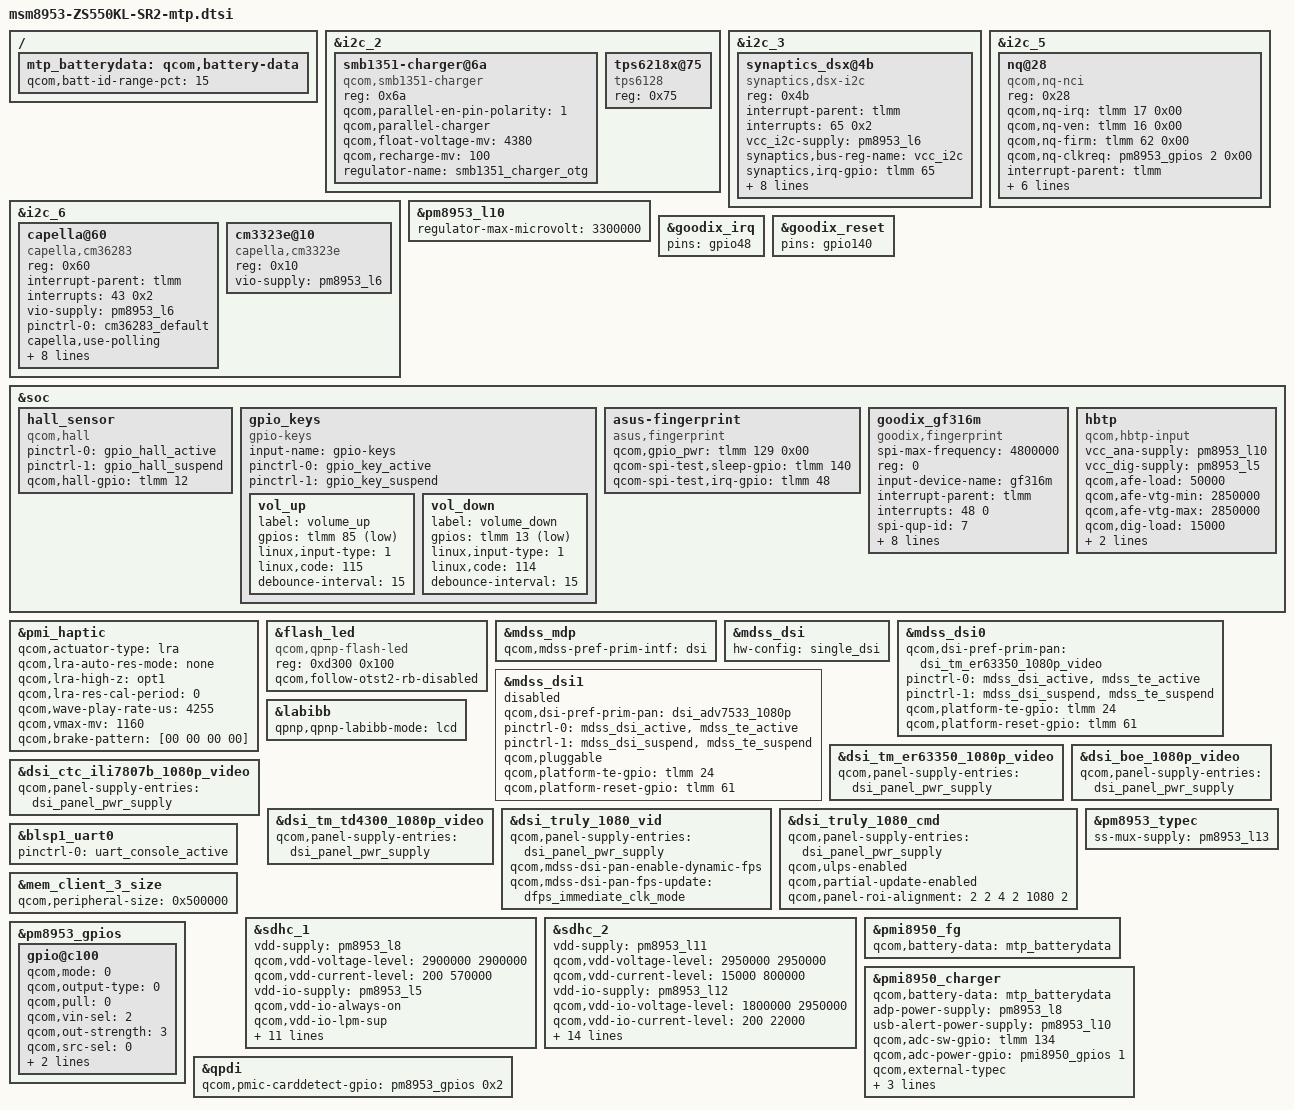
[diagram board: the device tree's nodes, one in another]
/*
 * Copyright (c) 2015-2016, The Linux Foundation. All rights reserved.
 *
 * This program is free software; you can redistribute it and/or modify
 * it under the terms of the GNU General Public License version 2 and
 * only version 2 as published by the Free Software Foundation.
 *
 * This program is distributed in the hope that it will be useful,
 * but WITHOUT ANY WARRANTY; without even the implied warranty of
 * MERCHANTABILITY or FITNESS FOR A PARTICULAR PURPOSE.  See the
 * GNU General Public License for more details.
 */

#include "msm8953-ZS550KL-SR2-pinctrl.dtsi"
#include "msm8953-ZS550KL-audio-mtp.dtsi"
#include "msm8953-ZS550KL-camera-sensor-mtp.dtsi"

&i2c_2 {
	/* Parallel-charger configuration */
	smb1351-charger@6a {
		compatible = "qcom,smb1351-charger";
		reg = <0x6a>;
		qcom,parallel-en-pin-polarity = <1>;
		qcom,parallel-charger;
		qcom,float-voltage-mv = <4380>;
		qcom,recharge-mv = <100>;
		regulator-name = "smb1351_charger_otg";
	};
	tps6218x@75{	
		compatible = "tps6128";
		reg = <0x75>;
		};
};

&i2c_3 { /* BLSP1 QUP3 */

	synaptics_dsx@4b {
		compatible = "synaptics,dsx-i2c";
		reg = <0x4b>;
		interrupt-parent = <&tlmm>;
		interrupts = <65 0x2>;
		//vdd_ana-supply = <&pm8941_l18>;
		vcc_i2c-supply = <&pm8953_l6>;
		//synaptics,pwr-reg-name = "vdd_ana";
		synaptics,bus-reg-name = "vcc_i2c";
		synaptics,irq-gpio = <&tlmm 65 0x00>;
		synaptics,irq-on-state = <0>;
		synaptics,irq-flags = <0x2008>; /* IRQF_ONESHOT | IRQF_TRIGGER_LOW */
		synaptics,power-delay-ms = <200>;
		synaptics,reset-delay-ms = <200>;
		synaptics,reset-on-state = <0>;
		synaptics,reset-active-ms = <20>;
		synaptics,ub-i2c-addr = <0x2c>;
		/* uncomment and update line below as appropriate if there are 0D buttons */
		synaptics,cap-button-codes = <158 102 139>;
		/* uncomment and update lines below as appropriate if there are virtual buttons */
		/* synaptics,vir-button-codes = <102 100 900 100 60 158 300 900 100 60>; */
		/* synaptics,max-y-for-2d = <800>; */
	};
};

&i2c_5 { /* BLSP2 QUP1 (NFC) */

	nq@28 {
		compatible = "qcom,nq-nci";
		reg = <0x28>;
		qcom,nq-irq = <&tlmm 17 0x00>;
		qcom,nq-ven = <&tlmm 16 0x00>;
		qcom,nq-firm = <&tlmm 62 0x00>;
		qcom,nq-clkreq = <&pm8953_gpios 2 0x00>;
		interrupt-parent = <&tlmm>;
		qcom,clk-src = "BBCLK2";
		interrupts = <17 0>;
		interrupt-names = "nfc_irq";
		pinctrl-names = "nfc_active", "nfc_suspend";
		pinctrl-0 = <&nfc_int_active &nfc_disable_active>;
		pinctrl-1 = <&nfc_int_suspend &nfc_disable_suspend>;
		clocks = <&clock_gcc clk_bb_clk2_pin>;
		clock-names = "ref_clk";
	};

};

&i2c_6 { /* BLSP2 QUP2 */
/*
	ap3045@1c{ 
		compatible = "di,ap3045";
		reg = <0x1c>;
		interrupt-parent = <&tlmm>;
		interrupts = <43 0>;
		vdd-supply = <&pm8953_l10>;
		//vcc_i2c-supply = <&pm8950_l6>;
		pinctrl-names = "default";
		pinctrl-0 = <&ap3045_default>;
		ap,use-polling;
		ap,interrupt-gpio = <&tlmm 43 0>;
		intel,ps-low-thres = < 70 >;
		intel,ps-hight-thres = < 80 >;
		intel,als-time = <0x10>;		
		intel,als-persis-time = <0x0f>;
		intel,int-ctrl = <0xA8>;
		intel,ps-gain = < 0x40 >; 
		intel,ps-led-control = <0x20>;
		intel,ps-time = <0x01>;  
		intel,als-gain = < 0x06 >;
		pm,class-name = "ap3045_class";
		pm,user-name = "ext_proximity_sensor";
		pm,state-D0 = "enable";
		pm,state-D3 = "disable";
		
	};
*/
	capella@60 {
		compatible = "capella,cm36283";
		reg = <0x60>;
		interrupt-parent = <&tlmm>;
		interrupts = <43 0x2>;
		//vdd-supply = <&pm8953_l10>;
		vio-supply = <&pm8953_l6>;
		pinctrl-names = "default";
		pinctrl-0 = <&cm36283_default>;
		capella,use-polling;
		capella,interrupt-gpio = <&tlmm 43 0x2>;
		capella,levels = <0x0A 0xA0 0xE1 0x140 0x280 0x500 0xA28 0x16A8 0x1F40 0x2800>;
		capella,ps_close_thd_set = <0x200>;
		capella,ps_away_thd_set = <0x100>;
		capella,ls_cmd = <0x04>; /* ALS_IT=80ms, INT_PERS=2*/
		capella,ps_conf1_val = <0x0006>;
		capella,ps_conf3_val = <0x3010>;
		};

	cm3323e@10{
		compatible = "capella,cm3323e";
		reg = <0x10>;
		//vdd-supply = <&pm8953_l10>;
		vio-supply = <&pm8953_l6>;
	};
};

&pm8953_l10 {
	regulator-max-microvolt = <3300000>;
};

&goodix_irq {
	pins = "gpio48";
};

&goodix_reset {
	pins = "gpio140";
};

&soc {
	hall_sensor {
		compatible = "qcom,hall";
		pinctrl-names = "hall_gpio_high","hall_gpio_low";
		pinctrl-0 = <&gpio_hall_active>;
		pinctrl-1 = <&gpio_hall_suspend>;
		qcom,hall-gpio = <&tlmm 12 0x0>;
	};

	gpio_keys {
		compatible = "gpio-keys";
		input-name = "gpio-keys";
		pinctrl-names = "tlmm_gpio_key_active","tlmm_gpio_key_suspend";
		pinctrl-0 = <&gpio_key_active>;
		pinctrl-1 = <&gpio_key_suspend>;

/* <ASUS_Lotta_Lu-2016/02/29> Note this beacuse because the gpio 87 is not for camera_focus ++++
		camera_focus {
			label = "camera_focus";
			gpios = <&tlmm 87 0x1>;
			linux,input-type = <1>;
			linux,code = <0x210>;
			debounce-interval = <15>;
		};
*/
/* <ASUS_Hank2_Liu-2016/08/02> Note this beacuse the gpio 86 is not for camera_snapshot ++++
		camera_snapshot {
			label = "camera_snapshot";
			gpios = <&tlmm 86 0x1>;
			linux,input-type = <1>;
			linux,code = <0x2fe>;
			debounce-interval = <15>;
		};
 <ASUS_Hank2_Liu-2016/08/02> Note this beacuse the gpio 86 is not for camera_snapshot ---- */
		vol_up {
			label = "volume_up";
			gpios = <&tlmm 85 0x1>;
			linux,input-type = <1>;
			linux,code = <115>;
			debounce-interval = <15>;
		};
//<ASUS_Hank2_Liu_20160217 Porting Volume Down Key> ++++++
		vol_down {
			label = "volume_down";
			gpios = <&tlmm 13 0x1>;
			linux,input-type = <1>;
			linux,code = <114>;
			debounce-interval = <15>;
		};
//<ASUS_Hank2_Liu_20160217 Porting Volume Down Key> ------
	};

	asus-fingerprint {
		compatible = "asus,fingerprint";
		//vcc-supply = <&pm8953_l6>;
		qcom,gpio_pwr = <&tlmm 129 0x00>;
		qcom-spi-test,sleep-gpio = <&tlmm 140 0x0>;
		qcom-spi-test,irq-gpio = <&tlmm 48 0x2008>;
	};

	goodix_gf316m {
		compatible = "goodix,fingerprint";
		spi-max-frequency = <4800000>;
		reg = <0>;
		input-device-name = "gf316m";
		interrupt-parent = <&tlmm>;
		interrupts = <48 0>;
		spi-qup-id = <7>;
		
		vcc_spi-supply  = <&pm8953_l6>;
		vdd_ana-supply  = <&pm8953_l6>;

		goodix,gpio_pwr = <&tlmm 129 0x00>;

		goodix,gpio_reset = <&tlmm 140 0x00>;
		goodix,gpio_irq = <&tlmm 48 0x00>;

		pinctrl-names = "goodix_irq_active";
		pinctrl-0 = <&goodix_irq_active>;

		clock-names = "iface_clk", "core_clk";
		clocks = <&clock_gcc clk_gcc_blsp2_ahb_clk>,
			 <&clock_gcc clk_gcc_blsp2_qup3_spi_apps_clk>;	
	};

	hbtp {
		compatible = "qcom,hbtp-input";
		vcc_ana-supply = <&pm8953_l10>;
		vcc_dig-supply = <&pm8953_l5>;
		qcom,afe-load = <50000>;
		qcom,afe-vtg-min = <2850000>;
		qcom,afe-vtg-max = <2850000>;
		qcom,dig-load = <15000>;
		qcom,dig-vtg-min = <1800000>;
		qcom,dig-vtg-max = <1800000>;
	};
};

&pmi_haptic{
	qcom,actuator-type = "lra";
	qcom,lra-auto-res-mode="none";
	qcom,lra-high-z="opt1";
	qcom,lra-res-cal-period = <0>;
	qcom,wave-play-rate-us = <4255>;
	qcom,vmax-mv = <1160>;
	qcom,brake-pattern = [00 00 00 00];
};

&flash_led {
	compatible = "qcom,qpnp-flash-led";
	reg = <0xd300 0x100>;
	qcom,follow-otst2-rb-disabled;
};

#include "msm8953-mdss-panels.dtsi"

&mdss_mdp {
	qcom,mdss-pref-prim-intf = "dsi";
};

&mdss_dsi {
	hw-config = "single_dsi";
};

&mdss_dsi0 {
	qcom,dsi-pref-prim-pan = <&dsi_tm_er63350_1080p_video>;
	pinctrl-names = "mdss_default", "mdss_sleep";
	pinctrl-0 = <&mdss_dsi_active &mdss_te_active>;
	pinctrl-1 = <&mdss_dsi_suspend &mdss_te_suspend>;

	qcom,platform-te-gpio = <&tlmm 24 0>;
	qcom,platform-reset-gpio = <&tlmm 61 0>;
	//qcom,platform-bklight-en-gpio = <&tlmm 59 0>;
};

&mdss_dsi1 {
	status = "disabled";
	qcom,dsi-pref-prim-pan = <&dsi_adv7533_1080p>;
	pinctrl-names = "mdss_default", "mdss_sleep";
	pinctrl-0 = <&mdss_dsi_active &mdss_te_active>;
	pinctrl-1 = <&mdss_dsi_suspend &mdss_te_suspend>;

	qcom,pluggable;
	qcom,platform-te-gpio = <&tlmm 24 0>;
	qcom,platform-reset-gpio = <&tlmm 61 0>;
	//qcom,platform-bklight-en-gpio = <&tlmm 59 0>;
};

&labibb {
	status = "ok";
	qpnp,qpnp-labibb-mode = "lcd";
};

//<ASUS_Hank2_Liu_20160217 Bring up Panel in Kernel> ++++++
&dsi_tm_er63350_1080p_video {
	qcom,panel-supply-entries = <&dsi_panel_pwr_supply>;
};

&dsi_ctc_ili7807b_1080p_video {
	qcom,panel-supply-entries = <&dsi_panel_pwr_supply>;
};

&dsi_boe_1080p_video {
	qcom,panel-supply-entries = <&dsi_panel_pwr_supply>;
};

&dsi_tm_td4300_1080p_video {
	qcom,panel-supply-entries = <&dsi_panel_pwr_supply>;
};
//<ASUS_Hank2_Liu_20160217 Bring up Panel in Kernel> ------

&dsi_truly_1080_vid {
	qcom,panel-supply-entries = <&dsi_panel_pwr_supply>;
	qcom,mdss-dsi-pan-enable-dynamic-fps;
	qcom,mdss-dsi-pan-fps-update = "dfps_immediate_clk_mode";
};

&dsi_truly_1080_cmd {
	qcom,panel-supply-entries = <&dsi_panel_pwr_supply>;
	qcom,ulps-enabled;
	qcom,partial-update-enabled;
	qcom,panel-roi-alignment = <2 2 4 2 1080 2>;
};

&blsp1_uart0 {
	status = "ok";
	pinctrl-names = "default";
	pinctrl-0 = <&uart_console_active>;
};

&mem_client_3_size {
	qcom,peripheral-size = <0x500000>;
};

&sdhc_1 {
	/* device core power supply */
	vdd-supply = <&pm8953_l8>;
	qcom,vdd-voltage-level = <2900000 2900000>;
	qcom,vdd-current-level = <200 570000>;

	/* device communication power supply */
	vdd-io-supply = <&pm8953_l5>;
	qcom,vdd-io-always-on;
	qcom,vdd-io-lpm-sup;
	qcom,vdd-io-voltage-level = <1800000 1800000>;
	qcom,vdd-io-current-level = <200 325000>;

	pinctrl-names = "active", "sleep";
	pinctrl-0 = <&sdc1_clk_on &sdc1_cmd_on &sdc1_data_on  &sdc1_rclk_on>;
	pinctrl-1 = <&sdc1_clk_off &sdc1_cmd_off &sdc1_data_off &sdc1_rclk_off>;

	qcom,clk-rates = <400000 20000000 25000000 50000000 100000000 192000000
								384000000>;
	qcom,nonremovable;
	qcom,bus-speed-mode = "HS400_1p8v", "HS200_1p8v", "DDR_1p8v";

	status = "ok";
};

&sdhc_2 {
	/* device core power supply */
	vdd-supply = <&pm8953_l11>;
	qcom,vdd-voltage-level = <2950000 2950000>;
	qcom,vdd-current-level = <15000 800000>;

	/* device communication power supply */
	vdd-io-supply = <&pm8953_l12>;
	qcom,vdd-io-voltage-level = <1800000 2950000>;
	qcom,vdd-io-current-level = <200 22000>;

	pinctrl-names = "active", "sleep";
	pinctrl-0 = <&sdc2_clk_on &sdc2_cmd_on &sdc2_data_on &sdc2_cd_on>;
	pinctrl-1 = <&sdc2_clk_off &sdc2_cmd_off &sdc2_data_off>;

	#address-cells = <0>;
	interrupt-parent = <&sdhc_2>;
	interrupts = <0 1 2>;
	#interrupt-cells = <1>;
	interrupt-map-mask = <0xffffffff>;
	interrupt-map = <0 &intc 0 125 0
		1 &intc 0 221 0
		2 &tlmm 133 0>;
	interrupt-names = "hc_irq", "pwr_irq", "status_irq";
	cd-gpios = <&tlmm 133 0x1>;

	qcom,clk-rates = <400000 20000000 25000000 50000000 100000000
								192000000>;
	qcom,bus-speed-mode = "SDR12", "SDR25", "SDR50", "DDR50", "SDR104";

	status = "ok";
};

&pm8953_typec {
	ss-mux-supply = <&pm8953_l13>;
	//qcom,ssmux-gpio = <&tlmm 139 GPIO_ACTIVE_HIGH>;
	//pinctrl-names = "default";
	//pinctrl-0 = <&typec_ssmux_config>;
};

/{
	mtp_batterydata: qcom,battery-data {
		qcom,batt-id-range-pct = <15>;
		#include "batterydata-itech-3000mah.dtsi"
		#include "2446501_Asus_Aquarius_3000mAh_averaged_MasterSlave_May26th2016_PMI8952GUI20016.dtsi"
	};
};

&pmi8950_fg {
	qcom,battery-data = <&mtp_batterydata>;
};

&pmi8950_charger {
	qcom,battery-data = <&mtp_batterydata>;
	adp-power-supply = <&pm8953_l8>;
	usb-alert-power-supply = <&pm8953_l10>;
	qcom,adc-sw-gpio=<&tlmm 134 0x0>;
	qcom,adc-power-gpio=<&pmi8950_gpios 1 0x0>;
	//qcom,chg-led-sw-controls;
	//qcom,chg-led-support;
	qcom,external-typec;
	qcom,typec-psy-name = "typec";
	usb-thermal-irq = <&tlmm 41 0x2008>;
	pinctrl-names = "default";
	pinctrl-0 = <&usb_thermal_irq_default>;
};

&pm8953_gpios {
	/* GPIO 2 (NFC_CLK_REQ) */
	gpio@c100 {
		qcom,mode = <0>;
		qcom,output-type = <0>;
		qcom,pull = <0>;
		qcom,vin-sel = <2>;
		qcom,out-strength = <3>;
		qcom,src-sel = <0>;
		qcom,master-en = <1>;
		qcom,dtest-sel = <1>;
		status = "okay";
	};
};

&qpdi {
	qcom,pmic-carddetect-gpio = <&pm8953_gpios 0x2 0>;
};
